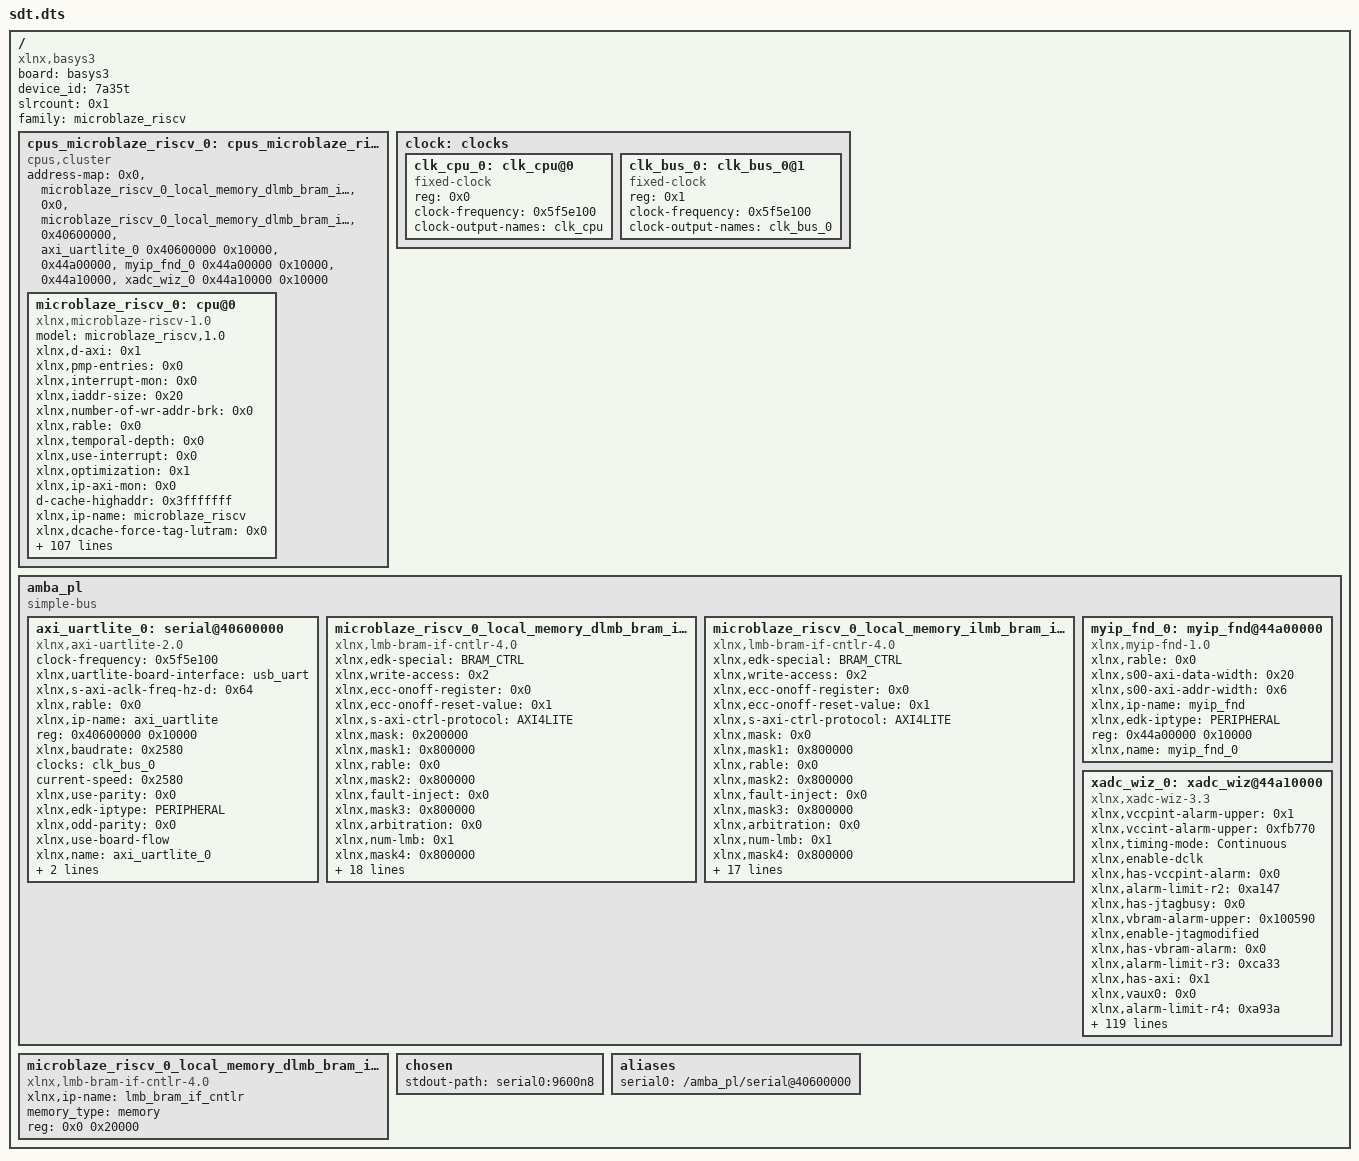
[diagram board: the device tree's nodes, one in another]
/dts-v1/;

/ {
        board = "basys3";
        compatible = "xlnx,basys3";
        device_id = "7a35t";
        #address-cells = <0x1>;
        #size-cells = <0x1>;
        slrcount = <0x1>;
        family = "microblaze_riscv";

        cpus_microblaze_riscv_0: cpus_microblaze_riscv@0 {
                #cpu-mask-cells = <0x1>;
                compatible = "cpus,cluster";
                #address-cells = <0x1>;
                #size-cells = <0x0>;
                address-map = <0x0 &microblaze_riscv_0_local_memory_dlmb_bram_if_cntlr_memory 0x0 0x20000>,
                 <0x0 &microblaze_riscv_0_local_memory_dlmb_bram_if_cntlr 0x0 0x20000>,
                 <0x40600000 &axi_uartlite_0 0x40600000 0x10000>,
                 <0x44a00000 &myip_fnd_0 0x44a00000 0x10000>,
                 <0x44a10000 &xadc_wiz_0 0x44a10000 0x10000>;
                #ranges-address-cells = <0x1>;
                #ranges-size-cells = <0x1>;
                phandle = <0x8>;

                microblaze_riscv_0: cpu@0 {
                        model = "microblaze_riscv,1.0";
                        xlnx,d-axi = <0x1>;
                        xlnx,pmp-entries = <0x0>;
                        xlnx,interrupt-mon = <0x0>;
                        xlnx,iaddr-size = <0x20>;
                        xlnx,number-of-wr-addr-brk = <0x0>;
                        xlnx,rable = <0x0>;
                        xlnx,temporal-depth = <0x0>;
                        xlnx,use-interrupt = <0x0>;
                        xlnx,optimization = <0x1>;
                        xlnx,ip-axi-mon = <0x0>;
                        d-cache-highaddr = <0x3fffffff>;
                        xlnx,ip-name = "microblaze_riscv";
                        xlnx,dcache-force-tag-lutram = <0x0>;
                        xlnx,pc-width = <0x11>;
                        xlnx,interrupt-is-edge = <0x0>;
                        reg = <0x0>;
                        xlnx,async-interrupt = <0x1>;
                        xlnx,use-mmu = <0x0>;
                        xlnx,icache-victims = <0x0>;
                        xlnx,use-bitman-a = <0x0>;
                        xlnx,d-lmb-mon = <0x0>;
                        xlnx,d-lmb-protocol = <0x0>;
                        xlnx,use-bitman-b = <0x0>;
                        xlnx,use-bitman-c = <0x0>;
                        xlnx,dc-axi-mon = <0x0>;
                        xlnx,debug-trace-async-reset = <0x0>;
                        xlnx,trace = <0x0>;
                        xlnx,part = "xc7a35tcpg236-1";
                        xlnx,use-config-reset = <0x0>;
                        xlnx,i-lmb-mon = <0x0>;
                        xlnx,dcache-byte-size = <0x1000>;
                        xlnx,ill-instr-exception = <0x1>;
                        compatible = "xlnx,microblaze-riscv-1.0", "xlnx,microblaze_riscv";
                        xlnx,data-size = <0x20>;
                        xlnx,fault-tolerant = <0x0>;
                        xlnx,use-sleep = <0x0>;
                        xlnx,debug-trace-size = <0x0>;
                        xlnx,pmp-granularity = <0x2>;
                        xlnx,mmu-privileged-instr = <0x0>;
                        d-cache-line-size = <0x10>;
                        xlnx,d-lmb = <0x1>;
                        xlnx,enable-discrete-ports = <0x0>;
                        clock-frequency = <0x5f5e100>;
                        xlnx,debug-interface = <0x0>;
                        xlnx,use-ext-brk = <0x0>;
                        xlnx,daddr-size = <0x20>;
                        xlnx,debug-enabled = <0x1>;
                        xlnx,num-sync-ff-dbg-trace-clk = <0x2>;
                        xlnx,i-lmb-protocol = <0x0>;
                        xlnx,fsl-exception = <0x0>;
                        xlnx,use-extended-fsl-instr = <0x0>;
                        xlnx,dp-axi-mon = <0x0>;
                        xlnx,impid = <0x1>;
                        device_type = "cpu";
                        xlnx,branch-target-cache-size = <0x0>;
                        xlnx,dcache-use-writeback = <0x0>;
                        xlnx,use-bitman-s = <0x0>;
                        bus-handle = <0x6>;
                        xlnx,icache-line-len = <0x4>;
                        xlnx,base-vectors = <0x0>;
                        xlnx,ecc-use-ce-exception = <0x0>;
                        xlnx,edk-special = "microblaze_riscv";
                        xlnx,use-dcache = <0x0>;
                        xlnx,use-barrel = <0x1>;
                        xlnx,use-muldiv = <0x2>;
                        xlnx,addr-size = <0x20>;
                        xlnx,debug-external-trace = <0x0>;
                        xlnx,piaddr-size = <0x20>;
                        xlnx,misaligned-exceptions = <0x1>;
                        xlnx,use-bitman = <0x0>;
                        xlnx,num-sync-ff-clk-debug = <0x2>;
                        xlnx,debug-event-counters = <0x0>;
                        xlnx,use-atomic = <0x0>;
                        xlnx,i-axi = <0x0>;
                        xlnx,g-template-list = <0x1>;
                        xlnx,icache-streams = <0x0>;
                        xlnx,dcache-line-len = <0x4>;
                        xlnx,num-sync-ff-clk = <0x2>;
                        xlnx,edk-iptype = "PROCESSOR";
                        xlnx,num-sync-ff-dbg-clk = <0x1>;
                        xlnx,interconnect = <0x2>;
                        xlnx,hartid = <0x0>;
                        xlnx,debug-latency-counters = <0x0>;
                        xlnx,use-fpu = <0x0>;
                        xlnx,icache-byte-size = <0x1000>;
                        xlnx,edge-is-positive = <0x1>;
                        xlnx,use-icache = <0x0>;
                        d-cache-size = <0x1000>;
                        xlnx,memory-ip-list = "microblaze_riscv_0_local_memory_dlmb_bram_if_cntlr_memory", "microblaze_riscv_0_local_memory_ilmb_bram_if_cntlr_memory";
                        xlnx,async-wakeup = <0x3>;
                        xlnx,use-non-secure = <0x0>;
                        xlnx,s-axi = <0x0>;
                        xlnx,number-of-rd-addr-brk = <0x0>;
                        d-cache-baseaddr = <0x0>;
                        xlnx,use-compression = <0x1>;
                        xlnx,avoid-primitives = <0x0>;
                        xlnx,use-counters = <0x1>;
                        xlnx,lockstep-slave = <0x0>;
                        xlnx,use-ext-nm-brk = <0x0>;
                        xlnx,pdaddr-size = <0x20>;
                        xlnx,instr-size = <0x20>;
                        xlnx,i-lmb = <0x1>;
                        xlnx,lockstep-select = <0x0>;
                        xlnx,lmb-data-size = <0x20>;
                        xlnx,ic-axi-mon = <0x0>;
                        xlnx,num-sync-ff-clk-irq = <0x1>;
                        xlnx,fsl-links = <0x0>;
                        timebase-frequency = <0x5f5e100>;
                        xlnx,archid = <0x1>;
                        xlnx,icache-force-tag-lutram = <0x0>;
                        xlnx,dcache-data-width = <0x0>;
                        xlnx,dcache-victims = <0x0>;
                        xlnx,use-branch-target-cache = <0x0>;
                        xlnx,debug-profile-size = <0x0>;
                        xlnx,lockstep-master = <0x0>;
                        xlnx,freq = <0x5f5e100>;
                        xlnx,number-of-pc-brk = <0x1>;
                        xlnx,imprecise-exceptions = <0x0>;
                        xlnx,icache-data-width = <0x0>;
                        xlnx,debug-counter-width = <0x40>;
                        phandle = <0x9>;
                };
        };

        clock: clocks {
                #address-cells = <0x1>;
                #size-cells = <0x0>;
                phandle = <0xa>;

                clk_cpu_0: clk_cpu@0 {
                        compatible = "fixed-clock";
                        reg = <0x0>;
                        clock-frequency = <0x5f5e100>;
                        clock-output-names = "clk_cpu";
                        #clock-cells = <0x0>;
                        phandle = <0xb>;
                };

                clk_bus_0: clk_bus_0@1 {
                        compatible = "fixed-clock";
                        reg = <0x1>;
                        clock-frequency = <0x5f5e100>;
                        clock-output-names = "clk_bus_0";
                        #clock-cells = <0x0>;
                        phandle = <0x7>;
                };
        };

        amba_pl: amba_pl {
                ranges;
                compatible = "simple-bus";
                #address-cells = <0x1>;
                #size-cells = <0x1>;
                phandle = <0x6>;

                axi_uartlite_0: serial@40600000 {
                        compatible = "xlnx,axi-uartlite-2.0", "xlnx,xps-uartlite-1.00.a";
                        clock-frequency = <0x5f5e100>;
                        xlnx,uartlite-board-interface = "usb_uart";
                        xlnx,s-axi-aclk-freq-hz-d = <0x64>;
                        xlnx,rable = <0x0>;
                        xlnx,ip-name = "axi_uartlite";
                        reg = <0x40600000 0x10000>;
                        xlnx,baudrate = <0x2580>;
                        clocks = <&clk_bus_0>;
                        current-speed = <0x2580>;
                        xlnx,use-parity = <0x0>;
                        xlnx,edk-iptype = "PERIPHERAL";
                        xlnx,odd-parity = <0x0>;
                        status = "okay";
                        xlnx,use-board-flow;
                        xlnx,name = "axi_uartlite_0";
                        xlnx,data-bits = <0x8>;
                        xlnx,parity = "No_Parity";
                        phandle = <0x3>;
                };

                microblaze_riscv_0_local_memory_dlmb_bram_if_cntlr: lmb_bram_if_cntlr@0 {
                        xlnx,edk-special = "BRAM_CTRL";
                        xlnx,write-access = <0x2>;
                        compatible = "xlnx,lmb-bram-if-cntlr-4.0";
                        xlnx,ecc-onoff-register = <0x0>;
                        xlnx,ecc-onoff-reset-value = <0x1>;
                        xlnx,s-axi-ctrl-protocol = "AXI4LITE";
                        xlnx,mask = <0x200000>;
                        xlnx,mask1 = <0x800000>;
                        xlnx,rable = <0x0>;
                        xlnx,mask2 = <0x800000>;
                        xlnx,fault-inject = <0x0>;
                        xlnx,mask3 = <0x800000>;
                        xlnx,arbitration = <0x0>;
                        xlnx,num-lmb = <0x1>;
                        xlnx,mask4 = <0x800000>;
                        reg = <0x0 0x20000>;
                        xlnx,s-axi-ctrl-addr-width = <0x20>;
                        xlnx,mask5 = <0x800000>;
                        xlnx,ecc-status-registers = <0x0>;
                        xlnx,mask6 = <0x800000>;
                        xlnx,lmb-protocol = <0x0>;
                        xlnx,ce-counter-width = <0x0>;
                        xlnx,mask7 = <0x800000>;
                        xlnx,ecc = <0x0>;
                        xlnx,edk-iptype = "PERIPHERAL";
                        xlnx,lmb-dwidth = <0x20>;
                        xlnx,ce-failing-registers = <0x0>;
                        xlnx,interconnect = <0x0>;
                        xlnx,ue-failing-registers = <0x0>;
                        xlnx,data-width = <0x20>;
                        xlnx,s-axi-ctrl-data-width = <0x20>;
                        xlnx,bram-awidth = <0x20>;
                        xlnx,lmb-awidth = <0x20>;
                        phandle = <0x2>;
                };

                microblaze_riscv_0_local_memory_ilmb_bram_if_cntlr: lmb_bram_if_cntlr@1 {
                        xlnx,edk-special = "BRAM_CTRL";
                        xlnx,write-access = <0x2>;
                        compatible = "xlnx,lmb-bram-if-cntlr-4.0";
                        xlnx,ecc-onoff-register = <0x0>;
                        xlnx,ecc-onoff-reset-value = <0x1>;
                        xlnx,s-axi-ctrl-protocol = "AXI4LITE";
                        xlnx,mask = <0x0>;
                        xlnx,mask1 = <0x800000>;
                        xlnx,rable = <0x0>;
                        xlnx,mask2 = <0x800000>;
                        xlnx,fault-inject = <0x0>;
                        xlnx,mask3 = <0x800000>;
                        xlnx,arbitration = <0x0>;
                        xlnx,num-lmb = <0x1>;
                        xlnx,mask4 = <0x800000>;
                        reg = <0x0 0x20000>;
                        xlnx,s-axi-ctrl-addr-width = <0x20>;
                        xlnx,mask5 = <0x800000>;
                        xlnx,ecc-status-registers = <0x0>;
                        xlnx,mask6 = <0x800000>;
                        xlnx,lmb-protocol = <0x0>;
                        xlnx,ce-counter-width = <0x0>;
                        xlnx,mask7 = <0x800000>;
                        xlnx,ecc = <0x0>;
                        xlnx,edk-iptype = "PERIPHERAL";
                        xlnx,lmb-dwidth = <0x20>;
                        xlnx,ce-failing-registers = <0x0>;
                        xlnx,interconnect = <0x0>;
                        xlnx,ue-failing-registers = <0x0>;
                        xlnx,s-axi-ctrl-data-width = <0x20>;
                        xlnx,bram-awidth = <0x20>;
                        xlnx,lmb-awidth = <0x20>;
                        phandle = <0xc>;
                };

                myip_fnd_0: myip_fnd@44a00000 {
                        xlnx,rable = <0x0>;
                        xlnx,s00-axi-data-width = <0x20>;
                        compatible = "xlnx,myip-fnd-1.0";
                        status = "okay";
                        xlnx,s00-axi-addr-width = <0x6>;
                        xlnx,ip-name = "myip_fnd";
                        xlnx,edk-iptype = "PERIPHERAL";
                        reg = <0x44a00000 0x10000>;
                        xlnx,name = "myip_fnd_0";
                        phandle = <0x4>;
                };

                xadc_wiz_0: xadc_wiz@44a10000 {
                        xlnx,vccpint-alarm-upper = <0x1>;
                        xlnx,vccint-alarm-upper = <0xfb770>;
                        xlnx,timing-mode = "Continuous";
                        xlnx,enable-dclk;
                        xlnx,has-vccpint-alarm = <0x0>;
                        xlnx,alarm-limit-r2 = <0xa147>;
                        xlnx,has-jtagbusy = <0x0>;
                        xlnx,vbram-alarm-upper = <0x100590>;
                        xlnx,enable-jtagmodified;
                        xlnx,has-vbram-alarm = <0x0>;
                        xlnx,alarm-limit-r3 = <0xca33>;
                        xlnx,has-axi = <0x1>;
                        xlnx,vaux0 = <0x0>;
                        xlnx,alarm-limit-r4 = <0xa93a>;
                        xlnx,has-busy = <0x1>;
                        xlnx,enable-channel;
                        xlnx,vaux1 = <0x0>;
                        xlnx,has-vccaux-alarm = <0x0>;
                        xlnx,alarm-limit-r5 = <0x52c6>;
                        xlnx,dclk-frequency = <0x64>;
                        xlnx,rable = <0x0>;
                        xlnx,vaux2 = <0x0>;
                        xlnx,alarm-limit-r6 = <0x9555>;
                        xlnx,vaux3 = <0x0>;
                        xlnx,ip-name = "xadc_wiz";
                        xlnx,alarm-limit-r7 = <0xae4e>;
                        xlnx,configuration-r0 = <0x3000>;
                        xlnx,has-drp = <0x0>;
                        xlnx,vaux4 = <0x0>;
                        xlnx,sim-file-rel-path = "./";
                        reg = <0x44a10000 0x10000>;
                        xlnx,alarm-limit-r8 = <0x5999>;
                        xlnx,configuration-r1 = <0x210f>;
                        xlnx,external-mux-channel = "VP_VN";
                        xlnx,temperature-alarm-trigger = <0x55>;
                        xlnx,vaux5 = <0x0>;
                        xlnx,alarm-limit-r9 = <0x5111>;
                        xlnx,configuration-r2 = <0x400>;
                        xlnx,has-jtaglocked = <0x0>;
                        xlnx,vaux6 = <0x1>;
                        xlnx,vaux7 = <0x0>;
                        xlnx,vaux8 = <0x0>;
                        xlnx,vaux9 = <0x0>;
                        xlnx,vaux10 = <0x0>;
                        xlnx,has-vn = <0x1>;
                        xlnx,has-vccpaux-alarm = <0x0>;
                        xlnx,acquisition-time = <0x4>;
                        xlnx,vaux11 = <0x0>;
                        xlnx,has-temp-bus = <0x0>;
                        xlnx,xadc-starup-selection = "channel_sequencer";
                        xlnx,enable-busy;
                        xlnx,data-width = <0x20>;
                        xlnx,vaux12 = <0x0>;
                        xlnx,sim-file-sel = "Default";
                        xlnx,has-vp = <0x1>;
                        xlnx,channel-enable-vauxp14-vauxn14;
                        xlnx,ip-type = <0x0>;
                        xlnx,temperature-alarm-ot-reset = <0x46>;
                        xlnx,vaux13 = <0x0>;
                        xlnx,enable-convst;
                        xlnx,vaux14 = <0x1>;
                        xlnx,vccpaux-alarm-lower = <0x1a17b0>;
                        xlnx,vccaux-alarm-lower = <0x1ab3f0>;
                        xlnx,vaux15 = <0x0>;
                        compatible = "xlnx,xadc-wiz-3.3", "xlnx,axi-xadc-1.00.a";
                        xlnx,has-external-mux = <0x0>;
                        xlnx,sampling-rate = <0xdf 0xe0288f62>;
                        xlnx,has-reset = <0x0>;
                        xlnx,adc-conversion-rate = <0x3e8>;
                        clock-frequency = <0x5f5e100>;
                        xlnx,vccddro-alarm-lower = <0x118c30>;
                        xlnx,enable-calibration-averaging;
                        xlnx,has-user-temp-alarm = <0x0>;
                        xlnx,has-ot-alarm = <0x0>;
                        xlnx,has-convst = <0x0>;
                        xlnx,single-channel-selection = "TEMPERATURE";
                        xlnx,startup-channel-selection = "single_channel";
                        xlnx,interface-selection = "Enable_AXI";
                        xlnx,vccpaux-alarm-upper = <0x1b7740>;
                        xlnx,vccaux-alarm-upper = <0x1cd6d0>;
                        status = "okay";
                        xlnx,vccddro-alarm-upper = <0x1312d0>;
                        xlnx,name = "xadc_wiz_0";
                        xlnx,external-mux = "none";
                        xlnx,enable-eoc;
                        xlnx,enable-jtaglocked;
                        xlnx,sim-file-name = "design";
                        xlnx,temperature-alarm-reset = <0x3c>;
                        xlnx,addr-width = <0x20>;
                        clocks = <&clk_bus_0>;
                        xlnx,alarm-limit-r10 = <0x5555>;
                        xlnx,alarm-limit-r11 = <0x5111>;
                        xlnx,alarm-limit-r12 = <0x9999>;
                        xlnx,edk-iptype = "PERIPHERAL";
                        xlnx,alarm-limit-r13 = <0x91eb>;
                        xlnx,sequencer-mode = "Continuous";
                        xlnx,enable-jtagbusy;
                        xlnx,alarm-limit-r14 = <0x6aaa>;
                        xlnx,include-intr = <0x1>;
                        xlnx,alarm-limit-r15 = <0x6222>;
                        xlnx,fifo-depth = <0x7>;
                        xlnx,has-eoc = <0x1>;
                        xlnx,temperature-alarm-ot-trigger = <0x7d>;
                        xlnx,has-channel = <0x1>;
                        xlnx,enable-eos;
                        xlnx,vccpint-alarm-lower = <0xe7ef0>;
                        xlnx,vccint-alarm-lower = <0xecd10>;
                        xlnx,has-dclk = <0x1>;
                        xlnx,vbram-alarm-lower = <0xe7ef0>;
                        xlnx,num-wave = <0x1>;
                        xlnx,sequence-r0 = <0x0>;
                        xlnx,has-jtagmodified = <0x0>;
                        xlnx,sequence-r1 = <0x4040>;
                        xlnx,channel-enable-vauxp6-vauxn6;
                        xlnx,enable-drp;
                        xlnx,sequence-r2 = <0x0>;
                        xlnx,has-vccint-alarm = <0x0>;
                        xlnx,channel-averaging = <0x100>;
                        xlnx,sequence-r3 = <0x0>;
                        xlnx,has-axi4stream = <0x0>;
                        xlnx,sequence-r4 = <0x0>;
                        xlnx,sequence-r5 = <0x0>;
                        xlnx,waveform-type = "CONSTANT";
                        xlnx,sequence-r6 = <0x0>;
                        xlnx,vccddro-volt = "1_2";
                        xlnx,sequence-r7 = <0x0>;
                        xlnx,has-vccddro-alarm = <0x0>;
                        xlnx,alarm-limit-r0 = <0xb5ed>;
                        xlnx,has-convstclk = <0x0>;
                        xlnx,has-eos = <0x1>;
                        xlnx,stimulus-freq = <0x1>;
                        xlnx,single-channel-enable-calibration;
                        xlnx,alarm-limit-r1 = <0x57e4>;
                        xlnx,component-name = "soc_adc_new_xadc_wiz_0_0";
                        xlnx,external-muxaddr-enable = <0x0>;
                        phandle = <0x5>;
                };
        };

        microblaze_riscv_0_local_memory_dlmb_bram_if_cntlr_memory: memory@0 {
                compatible = "xlnx,lmb-bram-if-cntlr-4.0";
                xlnx,ip-name = "lmb_bram_if_cntlr";
                device_type = "memory";
                memory_type = "memory";
                reg = <0x0 0x20000>;
                phandle = <0x1>;
        };

        chosen {
                stdout-path = "serial0:9600n8";
        };

        aliases {
                serial0 = "/amba_pl/serial@40600000";
        };

        __symbols__ {
                cpus_microblaze_riscv_0 = "/cpus_microblaze_riscv@0";
                microblaze_riscv_0 = "/cpus_microblaze_riscv@0/cpu@0";
                clock = "/clocks";
                clk_cpu_0 = "/clocks/clk_cpu@0";
                clk_bus_0 = "/clocks/clk_bus_0@1";
                amba_pl = "/amba_pl";
                axi_uartlite_0 = "/amba_pl/serial@40600000";
                microblaze_riscv_0_local_memory_dlmb_bram_if_cntlr = "/amba_pl/lmb_bram_if_cntlr@0";
                microblaze_riscv_0_local_memory_ilmb_bram_if_cntlr = "/amba_pl/lmb_bram_if_cntlr@1";
                myip_fnd_0 = "/amba_pl/myip_fnd@44a00000";
                xadc_wiz_0 = "/amba_pl/xadc_wiz@44a10000";
                microblaze_riscv_0_local_memory_dlmb_bram_if_cntlr_memory = "/memory@0";
        };
};
